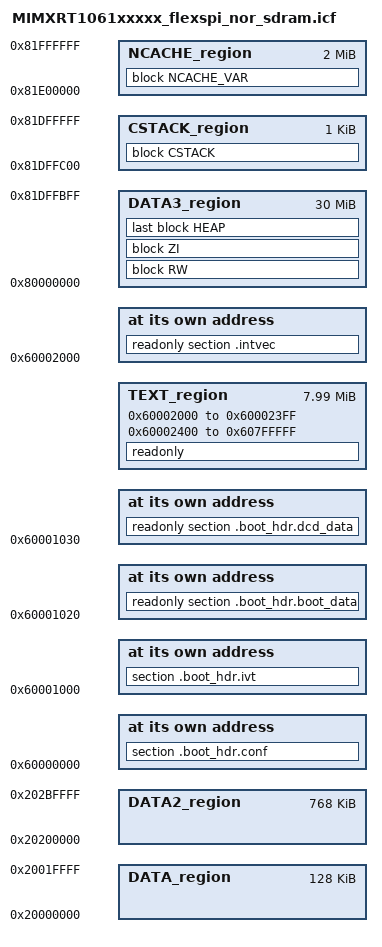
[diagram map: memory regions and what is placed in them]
/*
** ###################################################################
**     Processors:          MIMXRT1061CVJ5A
**                          MIMXRT1061CVL5A
**                          MIMXRT1061DVJ6A
**                          MIMXRT1061DVL6A
**
**     Compiler:            IAR ANSI C/C++ Compiler for ARM
**     Reference manual:    IMXRT1060RM Rev.1, 12/2018
**     Version:             rev. 0.1, 2017-01-10
**     Build:               b190312
**
**     Abstract:
**         Linker file for the IAR ANSI C/C++ Compiler for ARM
**
**     Copyright 2016 Freescale Semiconductor, Inc.
**     Copyright 2016-2019 NXP
**     All rights reserved.
**
**     SPDX-License-Identifier: BSD-3-Clause
**
**     http:                 www.nxp.com
**     mail:                 support@nxp.com
**
** ###################################################################
*/

define symbol m_interrupts_start       = 0x60002000;
define symbol m_interrupts_end         = 0x600023FF;

define symbol m_text_start             = 0x60002400;
define symbol m_text_end               = 0x607FFFFF;

define symbol m_data_start             = 0x20000000;
define symbol m_data_end               = 0x2001FFFF;

define symbol m_data2_start            = 0x20200000;
define symbol m_data2_end              = 0x202BFFFF;

define symbol m_data3_start            = 0x80000000;
define symbol m_data3_end              = 0x81DFFFFF;

define symbol m_ncache_start           = 0x81E00000;
define symbol m_ncache_end             = 0x81FFFFFF;

define exported symbol m_boot_hdr_conf_start = 0x60000000;
define symbol m_boot_hdr_ivt_start           = 0x60001000;
define symbol m_boot_hdr_boot_data_start     = 0x60001020;
define symbol m_boot_hdr_dcd_data_start      = 0x60001030;

/* Sizes */
if (isdefinedsymbol(__stack_size__)) {
  define symbol __size_cstack__        = __stack_size__;
} else {
  define symbol __size_cstack__        = 0x0400;
}

if (isdefinedsymbol(__heap_size__)) {
  define symbol __size_heap__          = __heap_size__;
} else {
  define symbol __size_heap__          = 0x0400;
}

define exported symbol __VECTOR_TABLE  = m_interrupts_start;
define exported symbol __VECTOR_RAM    = m_interrupts_start;
define exported symbol __RAM_VECTOR_TABLE_SIZE = 0x0;

define memory mem with size = 4G;
define region TEXT_region = mem:[from m_interrupts_start to m_interrupts_end]
                          | mem:[from m_text_start to m_text_end];

define region DATA_region = mem:[from m_data_start to m_data_end];
define region DATA2_region = mem:[from m_data2_start to m_data2_end];
define region DATA3_region  = mem:[from m_data3_start to m_data3_end-__size_cstack__];
define region CSTACK_region = mem:[from m_data3_end-__size_cstack__+1 to m_data3_end];
define region NCACHE_region = mem:[from m_ncache_start to m_ncache_end];

define block CSTACK    with alignment = 8, size = __size_cstack__   { };
define block HEAP      with alignment = 8, size = __size_heap__     { };
define block RW        { first readwrite, section m_usb_dma_init_data };
define block ZI         with alignment = 32  { first zi, section m_usb_dma_noninit_data };
define block NCACHE_VAR with size = 0x200000 , alignment = 0x100000  { section NonCacheable , section NonCacheable.init };

initialize by copy { readwrite, section .textrw };
do not initialize  { section .noinit };

place at address mem: m_interrupts_start    { readonly section .intvec };

place at address mem:m_boot_hdr_conf_start { section .boot_hdr.conf };
place at address mem:m_boot_hdr_ivt_start { section .boot_hdr.ivt };
place at address mem:m_boot_hdr_boot_data_start { readonly section .boot_hdr.boot_data };
place at address mem:m_boot_hdr_dcd_data_start { readonly section .boot_hdr.dcd_data };

keep{ section .boot_hdr.conf, section .boot_hdr.ivt, section .boot_hdr.boot_data, section .boot_hdr.dcd_data };

place in TEXT_region                        { readonly };
place in DATA3_region                       { block RW };
place in DATA3_region                       { block ZI };
place in DATA3_region                       { last block HEAP };
place in CSTACK_region                      { block CSTACK };
place in NCACHE_region                      { block NCACHE_VAR };

